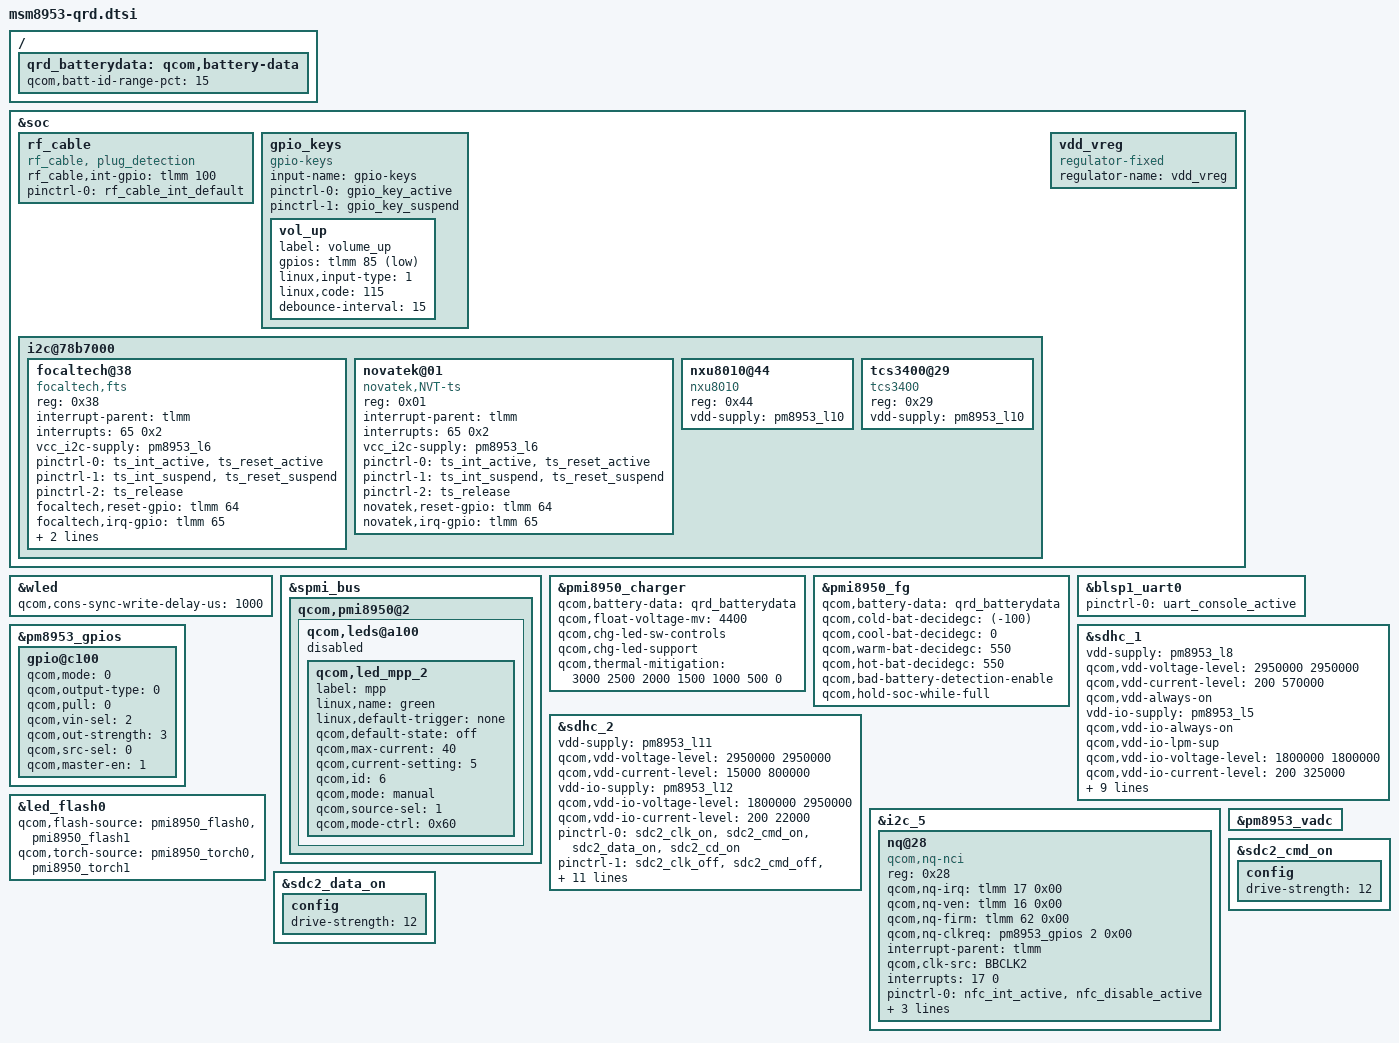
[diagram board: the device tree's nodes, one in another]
/*
 * Copyright (c) 2015-2016, The Linux Foundation. All rights reserved.
 *
 * This program is free software; you can redistribute it and/or modify
 * it under the terms of the GNU General Public License version 2 and
 * only version 2 as published by the Free Software Foundation.
 *
 * This program is distributed in the hope that it will be useful,
 * but WITHOUT ANY WARRANTY; without even the implied warranty of
 * MERCHANTABILITY or FITNESS FOR A PARTICULAR PURPOSE.  See the
 * GNU General Public License for more details.
 */

#include "msm8953-pinctrl.dtsi"
#include "u3-p1-msm8953-camera-odin.dtsi"
/* #include "msm8953-camera-sensor-qrd.dtsi" */

&soc {
	rf_cable {
		compatible = "rf_cable, plug_detection";
		rf_cable,int-gpio = <&tlmm 100 0>;
		pinctrl-names = "default";
		pinctrl-0 = <&rf_cable_int_default>;
	};
	gpio_keys {
		compatible = "gpio-keys";
		input-name = "gpio-keys";
		pinctrl-names = "tlmm_gpio_key_active","tlmm_gpio_key_suspend";
		pinctrl-0 = <&gpio_key_active>;
		pinctrl-1 = <&gpio_key_suspend>;

		vol_up {
			label = "volume_up";
			gpios = <&tlmm 85 0x1>;
			linux,input-type = <1>;
			linux,code = <115>;
			debounce-interval = <15>;
		};

	};

	i2c@78b7000 { /* BLSP1 QUP3 */
		status = "okay";

		focaltech@38 {
			compatible = "focaltech,fts";
			reg = <0x38>;
			interrupt-parent = <&tlmm>;
			interrupts = <65 0x2>;
			vcc_i2c-supply = <&pm8953_l6>;
			/* pins used by touchscreen */
			pinctrl-names = "pmx_ts_active","pmx_ts_suspend","pmx_ts_release";
			pinctrl-0 = <&ts_int_active &ts_reset_active>;
			pinctrl-1 = <&ts_int_suspend &ts_reset_suspend>;
			pinctrl-2 = <&ts_release>;
			focaltech,reset-gpio = <&tlmm 64 0x0>;
			focaltech,irq-gpio = <&tlmm 65 0x2008>;
			focaltech,max-touch-number = <10>;
			focaltech,display-coords = <0 0 1080 1920>;
		};

		novatek@01 {
			compatible = "novatek,NVT-ts";
			reg = <0x01>;
			interrupt-parent = <&tlmm>;
			interrupts = <65 0x2>;
			vcc_i2c-supply = <&pm8953_l6>;
			pinctrl-names = "pmx_ts_active","pmx_ts_suspend","pmx_ts_release";
			pinctrl-0 = <&ts_int_active &ts_reset_active>;
			pinctrl-1 = <&ts_int_suspend &ts_reset_suspend>;
			pinctrl-2 = <&ts_release>;
			novatek,reset-gpio = <&tlmm 64 0x0>;
			novatek,irq-gpio = <&tlmm 65 0x2008>;
		};
		//Begin:xiaopeng Add RGBW sensor into I2C-3 bus 2016-11-9
		nxu8010@44 {
			compatible = "nxu8010";
			reg = <0x44>;
			vdd-supply = <&pm8953_l10>;
		};
		//End:xiaopeng Add RGBW sensor into I2C-3 bus 2016-11-9
		//Begin:xiaopeng Add RGBW sensor into I2C-3 bus 2016-12-9
		tcs3400@29 {
			compatible = "tcs3400";
			reg = <0x29>;
			vdd-supply = <&pm8953_l10>;
		};
		//End:xiaopeng Add RGBW sensor into I2C-3 bus 2016-12-9
	};

	vdd_vreg: vdd_vreg {
		compatible = "regulator-fixed";
		status = "ok";
		regulator-name = "vdd_vreg";
	};
};

&wled {
	qcom,cons-sync-write-delay-us = <1000>;
};

&spmi_bus {
	qcom,pmi8950@2 {
		qcom,leds@a100 {
			status = "disabled";
			qcom,led_mpp_2 {
				label = "mpp";
				linux,name = "green";
				linux,default-trigger = "none";
				qcom,default-state = "off";
				qcom,max-current = <40>;
				qcom,current-setting = <5>;
				qcom,id = <6>;
				qcom,mode = "manual";
				qcom,source-sel = <1>;
				qcom,mode-ctrl = <0x60>;
			};
		};
	};
};

/ {
	qrd_batterydata: qcom,battery-data {
		qcom,batt-id-range-pct = <15>;
		#include "batterydata-smartisan-atl-4v4-3500mah.dtsi"
		#include "batterydata-smartisan-scud-4v4-3500mah.dtsi"
	};
};
/*
&pm8953_typec {
	ss-mux-supply = <&pm8953_l6>;
	qcom,ssmux-gpio = <&tlmm 139 GPIO_ACTIVE_LOW>;
	pinctrl-names = "default";
	pinctrl-0 = <&typec_ssmux_config>;
};
#endif
*/
&pmi8950_charger {
	qcom,battery-data = <&qrd_batterydata>;
	qcom,float-voltage-mv = <4400>;
	qcom,chg-led-sw-controls;
	qcom,chg-led-support;
/*	qcom,external-typec;*/
/*	qcom,typec-psy-name = "typec";*/
	qcom,thermal-mitigation = <3000 2500 2000 1500 1000 500 0>;
	status = "okay";
};

&pmi8950_fg {
	qcom,battery-data = <&qrd_batterydata>;
	qcom,cold-bat-decidegc = <(-100)>;
	qcom,cool-bat-decidegc = <0>;
	qcom,warm-bat-decidegc = <550>;
	qcom,hot-bat-decidegc = <550>;
	qcom,bad-battery-detection-enable;
	qcom,hold-soc-while-full;
};

&blsp1_uart0 {
	status = "ok";
	pinctrl-names = "default";
	pinctrl-0 = <&uart_console_active>;
};

&sdhc_1 {
	/* device core power supply */
	vdd-supply = <&pm8953_l8>;
	qcom,vdd-voltage-level = <2950000 2950000>;
	qcom,vdd-current-level = <200 570000>;
	qcom,vdd-always-on;

	/* device communication power supply */
	vdd-io-supply = <&pm8953_l5>;
	qcom,vdd-io-always-on;
	qcom,vdd-io-lpm-sup;
	qcom,vdd-io-voltage-level = <1800000 1800000>;
	qcom,vdd-io-current-level = <200 325000>;

	pinctrl-names = "active", "sleep";
	pinctrl-0 = <&sdc1_clk_on &sdc1_cmd_on &sdc1_data_on &sdc1_rclk_on>;
	pinctrl-1 = <&sdc1_clk_off &sdc1_cmd_off &sdc1_data_off &sdc1_rclk_off>;

	qcom,clk-rates = <400000 20000000 25000000 50000000 100000000 192000000
								384000000>;
	qcom,nonremovable;
	qcom,bus-speed-mode = "HS400_1p8v", "HS200_1p8v", "DDR_1p8v";

	status = "ok";
};

&sdhc_2 {
	/* device core power supply */
	vdd-supply = <&pm8953_l11>;
	qcom,vdd-voltage-level = <2950000 2950000>;
	qcom,vdd-current-level = <15000 800000>;

	/* device communication power supply */
	vdd-io-supply = <&pm8953_l12>;
	qcom,vdd-io-voltage-level = <1800000 2950000>;
	qcom,vdd-io-current-level = <200 22000>;

	pinctrl-names = "active", "sleep";
	pinctrl-0 = <&sdc2_clk_on &sdc2_cmd_on &sdc2_data_on &sdc2_cd_on>;
	pinctrl-1 = <&sdc2_clk_off &sdc2_cmd_off &sdc2_data_off &sdc2_cd_off>;

	#address-cells = <0>;
	interrupt-parent = <&sdhc_2>;
	interrupts = <0 1 2>;
	#interrupt-cells = <1>;
	interrupt-map-mask = <0xffffffff>;
	interrupt-map = <0 &intc 0 125 0
		1 &intc 0 221 0
		2 &tlmm 133 0>;
	interrupt-names = "hc_irq", "pwr_irq", "status_irq";
	cd-gpios = <&tlmm 133 0x0>;

	qcom,clk-rates = <400000 20000000 25000000 50000000 100000000
								200000000>;
	qcom,bus-speed-mode = "SDR12", "SDR25", "SDR50", "DDR50", "SDR104";

	status = "ok";
};

&i2c_5 { /* BLSP2 QUP1 (NFC) */
	nq@28 {
		compatible = "qcom,nq-nci";
		reg = <0x28>;
		qcom,nq-irq = <&tlmm 17 0x00>;
		qcom,nq-ven = <&tlmm 16 0x00>;
		qcom,nq-firm = <&tlmm 62 0x00>;
		qcom,nq-clkreq = <&pm8953_gpios 2 0x00>;
		interrupt-parent = <&tlmm>;
		qcom,clk-src = "BBCLK2";
		interrupts = <17 0>;
		interrupt-names = "nfc_irq";
		pinctrl-names = "nfc_active", "nfc_suspend";
		pinctrl-0 = <&nfc_int_active &nfc_disable_active>;
		pinctrl-1 = <&nfc_int_suspend &nfc_disable_suspend>;
		clocks = <&clock_gcc clk_bb_clk2_pin>;
		clock-names = "ref_clk";
	};
};

&pm8953_gpios {
	/* GPIO 2 (NFC_CLK_REQ) */
	gpio@c100 {
		qcom,mode = <0>;
		qcom,output-type = <0>;
		qcom,pull = <0>;
		qcom,vin-sel = <2>;
		qcom,out-strength = <3>;
		qcom,src-sel = <0>;
		qcom,master-en = <1>;
		status = "okay";
	};
};

/*  //lijiankun add flash_1&torch_1 node  2016-11-22
&flash_led {
	/delete-node/ qcom,flash_1;
	/delete-node/ qcom,torch_1;
};
*/

&led_flash0{
	qcom,flash-source = <&pmi8950_flash0 &pmi8950_flash1>;//lijiankun add pmi8950_flash1 & pmi8950_torch1 for flash 2016-11-22
	qcom,torch-source = <&pmi8950_torch0 &pmi8950_torch1>;//lijiankun add pmi8950_flash1 & pmi8950_torch1 for flash 2016-11-22
};

&pm8953_vadc {
	/delete-node/ chan@11;
};

&sdc2_cmd_on {
	config {
		drive-strength=<12>;
	};
};

&sdc2_data_on {
	config {
		drive-strength=<12>;
	};
};
